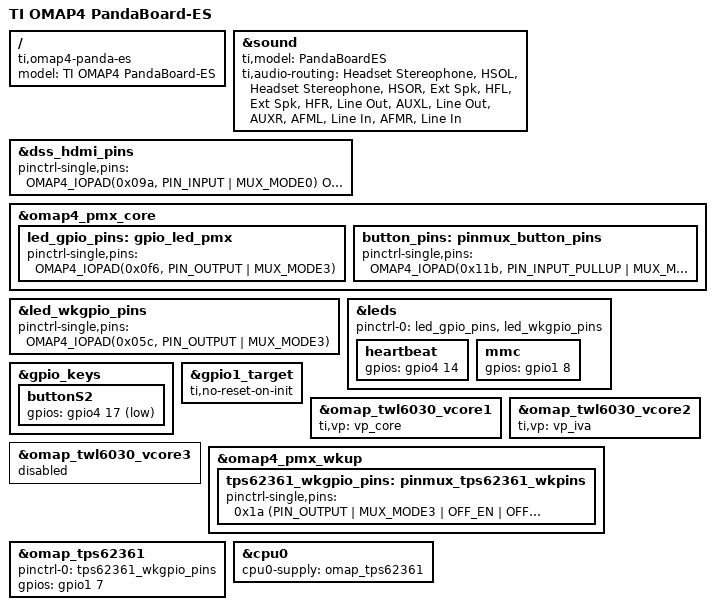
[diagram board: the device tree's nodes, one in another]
/*
 * Copyright (C) 2012 Texas Instruments Incorporated - http://www.ti.com/
 *
 * This program is free software; you can redistribute it and/or modify
 * it under the terms of the GNU General Public License version 2 as
 * published by the Free Software Foundation.
 */
/dts-v1/;

#include "omap4460.dtsi"
#include "omap4-panda-common.dtsi"

/ {
	model = "TI OMAP4 PandaBoard-ES";
	compatible = "ti,omap4-panda-es", "ti,omap4-panda", "ti,omap4460", "ti,omap4430", "ti,omap4";
};

/* Audio routing is differnet between PandaBoard4430 and PandaBoardES */
&sound {
	ti,model = "PandaBoardES";

	/* Audio routing */
	ti,audio-routing =
		"Headset Stereophone", "HSOL",
		"Headset Stereophone", "HSOR",
		"Ext Spk", "HFL",
		"Ext Spk", "HFR",
		"Line Out", "AUXL",
		"Line Out", "AUXR",
		"AFML", "Line In",
		"AFMR", "Line In";
};

/* PandaboardES has external pullups on SCL & SDA */
&dss_hdmi_pins {
	pinctrl-single,pins = <
		OMAP4_IOPAD(0x09a, PIN_INPUT | MUX_MODE0)		/* hdmi_cec.hdmi_cec */
		OMAP4_IOPAD(0x09c, PIN_INPUT | MUX_MODE0)		/* hdmi_scl.hdmi_scl */
		OMAP4_IOPAD(0x09e, PIN_INPUT | MUX_MODE0)		/* hdmi_sda.hdmi_sda */
		>;
};

&omap4_pmx_core {
	led_gpio_pins: gpio_led_pmx {
		pinctrl-single,pins = <
			OMAP4_IOPAD(0x0f6, PIN_OUTPUT | MUX_MODE3)	/* gpio_110 */
		>;
	};

	button_pins: pinmux_button_pins {
		pinctrl-single,pins = <
			OMAP4_IOPAD(0x11b, PIN_INPUT_PULLUP | MUX_MODE3) /* gpio_113 */
		>;
	};
};

&led_wkgpio_pins {
	pinctrl-single,pins = <
		OMAP4_IOPAD(0x05c, PIN_OUTPUT | MUX_MODE3)	/* gpio_wk8 */
	>;
};

&leds {
	pinctrl-0 = <
		&led_gpio_pins
		&led_wkgpio_pins
	>;

	heartbeat {
		gpios = <&gpio4 14 GPIO_ACTIVE_HIGH>;
	};
	mmc {
		gpios = <&gpio1 8 GPIO_ACTIVE_HIGH>;
	};
};

&gpio_keys {
	buttonS2 {
		gpios = <&gpio4 17 GPIO_ACTIVE_LOW>; /* gpio_113 */
	};
};

&gpio1_target {
	 ti,no-reset-on-init;
};

&omap_twl6030_vcore1 {
	ti,vp = <&vp_core>;
};

&omap_twl6030_vcore2 {
	ti,vp = <&vp_iva>;
};

&omap_twl6030_vcore3 {
	/* We use TPS62361 on this platform instead */
	status = "disabled";
};

#include "tps62361_omap.dtsi"

&omap4_pmx_wkup {
	tps62361_wkgpio_pins: pinmux_tps62361_wkpins {
		pinctrl-single,pins = <
			0x1a (PIN_OUTPUT | MUX_MODE3 | OFF_EN | OFFOUT_VAL) /* gpio_wk7 */
		>;
	};
};

&omap_tps62361 {
	pinctrl-names = "default";
	pinctrl-0 = <
		&tps62361_wkgpio_pins
	>;
	gpios = <&gpio1 7 GPIO_ACTIVE_HIGH>;
};

&cpu0 {
	cpu0-supply = <&omap_tps62361>;
};
